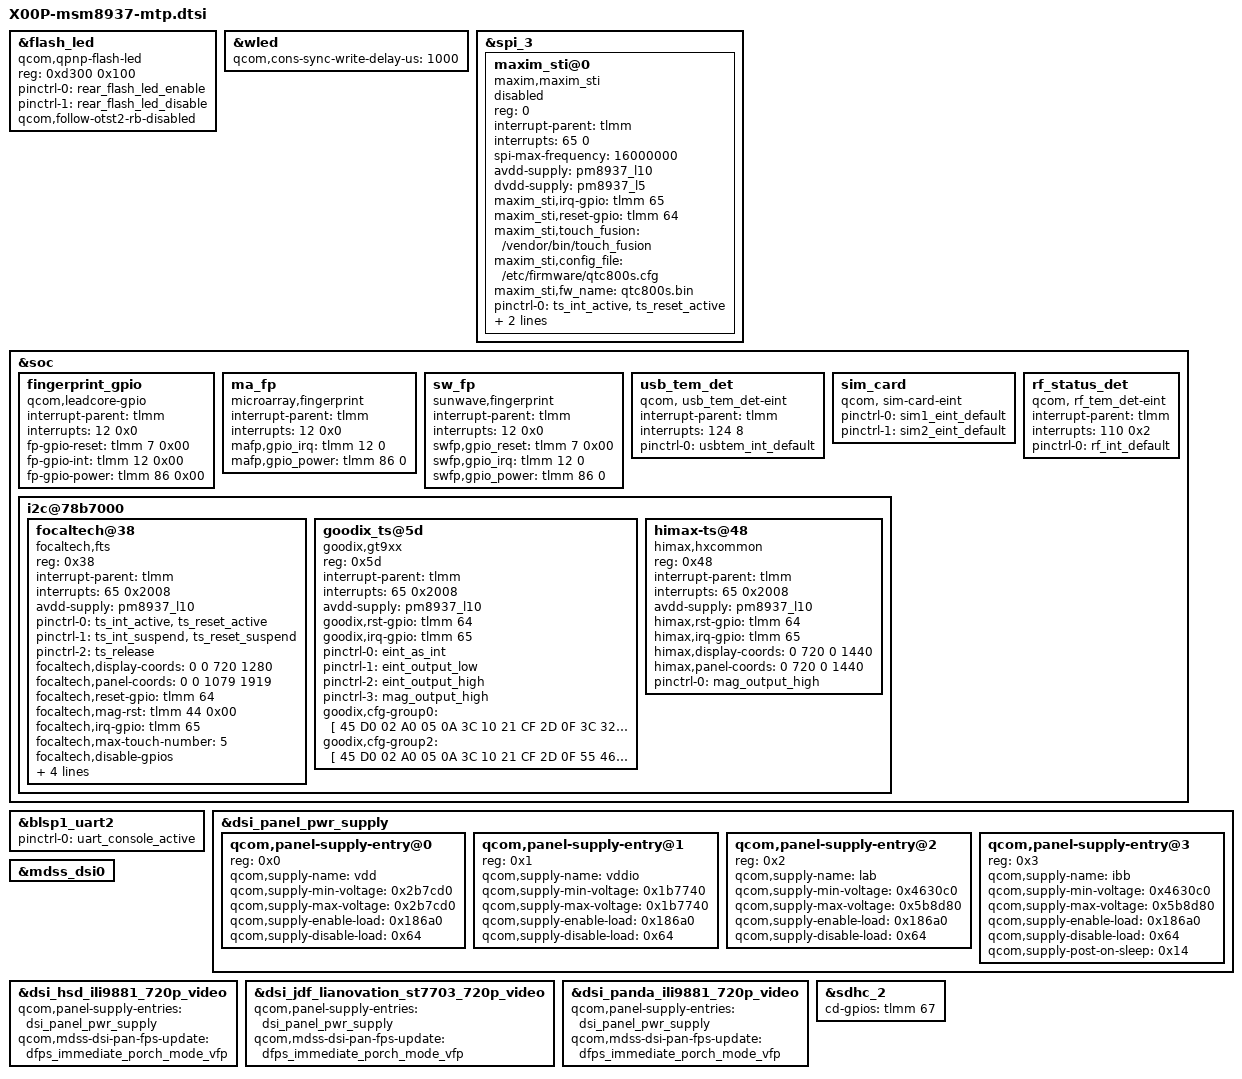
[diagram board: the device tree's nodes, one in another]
/*
 * Copyright (c) 2017, The Linux Foundation. All rights reserved.
 *
 * This program is free software; you can redistribute it and/or modify
 * it under the terms of the GNU General Public License version 2 and
 * only version 2 as published by the Free Software Foundation.
 *
 * This program is distributed in the hope that it will be useful,
 * but WITHOUT ANY WARRANTY; without even the implied warranty of
 * MERCHANTABILITY or FITNESS FOR A PARTICULAR PURPOSE.  See the
 * GNU General Public License for more details.
 */

&flash_led {
	/delete-property/ compatible;
	/delete-property/ reg;
	/delete-property/ pinctrl-names;
	/delete-property/ pinctrl-0;
	/delete-property/ pinctrl-1;
	/delete-property/ qcom,follow-otst2-rb-disabled;
};

&wled {
	/delete-property/ qcom,cons-sync-write-delay-us;
};

&spi_3 {
	maxim_sti@0 {
		status = "disabled";
		compatible = "maxim,maxim_sti";
		reg = <0>;
		interrupt-parent = <&tlmm>;
		interrupts = <65 0>;
		spi-max-frequency = <16000000>;
		avdd-supply = <&pm8937_l10>;
		dvdd-supply = <&pm8937_l5>;
		maxim_sti,irq-gpio = <&tlmm 65 0x00>;
		maxim_sti,reset-gpio = <&tlmm 64 0x00>;
		maxim_sti,touch_fusion = "/vendor/bin/touch_fusion";
		maxim_sti,config_file = "/etc/firmware/qtc800s.cfg";
		maxim_sti,fw_name = "qtc800s.bin";
		pinctrl-names = "pmx_ts_active","pmx_ts_suspend",
			"pmx_ts_release";
		pinctrl-0 = <&ts_int_active &ts_reset_active>;
		pinctrl-1 = <&ts_int_suspend &ts_reset_suspend>;
		pinctrl-2 = <&ts_release>;
	};
};

&soc {
	fingerprint_gpio {
		compatible = "qcom,leadcore-gpio";
		interrupt-parent = <&tlmm>;
		interrupts = <12 0x0>;

		fp-gpio-reset = <&tlmm 7 0x00>;
		fp-gpio-int = <&tlmm  12 0x00>;
		fp-gpio-power = <&tlmm  86 0x00>;
		status = "okay";
	};

	ma_fp {
		compatible = "microarray,fingerprint";
		interrupt-parent = <&tlmm>;
		interrupts = <12 0x0>;
		mafp,gpio_irq = <&tlmm 12 0>;
		mafp,gpio_power = <&tlmm 86 0>;
	};

	sw_fp {
		compatible = "sunwave,fingerprint";
		interrupt-parent = <&tlmm>;
		interrupts = <12 0x0>;
		swfp,gpio_reset = <&tlmm 7 0x00>;
		swfp,gpio_irq = <&tlmm 12 0>;
		swfp,gpio_power = <&tlmm 86 0>;
		status = "okay";
    };	

	usb_tem_det: usb_tem_det {
		compatible = "qcom, usb_tem_det-eint";
    	interrupt-parent = <&tlmm>;
		interrupts = <124 8>;
		pinctrl-names = "default";
		pinctrl-0 = <&usbtem_int_default>;
		status = "okay";
	};	
	
	sim_card: sim_card {
		compatible = "qcom, sim-card-eint";
		pinctrl-names = "sim1_default","sim2_default";
		pinctrl-0 = <&sim1_eint_default>;
		pinctrl-1 = <&sim2_eint_default>;
		status = "ok";
	};

	rf_status_det: rf_status_det {
		compatible = "qcom, rf_tem_det-eint";
		interrupt-parent = <&tlmm>;
		interrupts = <110 0x2>;
		pinctrl-names = "rfstatus";
		pinctrl-0 = <&rf_int_default>;
	};
	
	i2c@78b7000 {
		status = "ok";

		focaltech@38 {
			compatible = "focaltech,fts";
			reg = <0x38>;
			interrupt-parent = <&tlmm>;
			interrupts = <65 0x2008>;
			avdd-supply = <&pm8937_l10>;
			pinctrl-names = "pmx_ts_active","pmx_ts_suspend",
				"pmx_ts_release";
			pinctrl-0 = <&ts_int_active &ts_reset_active>;
			pinctrl-1 = <&ts_int_suspend &ts_reset_suspend>;
			pinctrl-2 = <&ts_release>;
			focaltech,display-coords = <0 0 720 1280>;
			focaltech,panel-coords = <0 0 1079 1919>;
			focaltech,reset-gpio = <&tlmm 64 0x00>;
			focaltech,mag-rst = <&tlmm 44 0x00>;
			focaltech,irq-gpio = <&tlmm 65 0x2008>;
			focaltech,max-touch-number = <5>;
			focaltech,disable-gpios;
			focaltech,button-map = <158 139 172>;
			focaltech,resume-in-workqueue;
			clock-names = "iface_clk", "core_clk";
			clocks = <&clock_gcc clk_gcc_blsp1_ahb_clk>,
				<&clock_gcc clk_gcc_blsp1_qup3_i2c_apps_clk>;
		};

		goodix_ts@5d {
			compatible = "goodix,gt9xx";
			reg = <0x5d>;
			interrupt-parent = <&tlmm>;
			interrupts = <65 0x2008>;
			avdd-supply = <&pm8937_l10>;
			goodix,rst-gpio = <&tlmm 64 0x00>;
			goodix,irq-gpio = <&tlmm 65 0x2008>;
			pinctrl-names = "eint_as_int","eint_output_low", "eint_output_high", "mag_output_high";
			pinctrl-0 = <&eint_as_int>;
			pinctrl-1 = <&eint_output_low>;
			pinctrl-2 = <&eint_output_high>;
			pinctrl-3 = <&mag_output_high>;
			
			goodix,cfg-group0 = [
				45 D0 02 A0 05 0A 3C 10 21 CF 2D
				0F 3C 32 05 F3 00 00 60 62 00 11
				06 15 16 1A 14 87 27 DD 4C 4E D3
				07 7C 06 00 A2 34 11 00 0A 03 02
				19 00 40 0A 0C 62 2A 32 82 88 80
				A5 0A 1E 1E 04 A9 37 00 91 42 00
				7C 50 00 6A 62 00 5D 76 00 5D 00
				00 00 00 F0 50 40 FF F0 17 00 20
				00 03 00 00 00 00 53 64 04 04 0F
				28 00 00 00 00 00 0A 50 19 1E 00
				1E 28 19 18 17 16 15 14 13 12 11
				10 0F 0E 0B 04 05 0C 0D 08 09 0A
				03 02 01 00 07 06 FF FF FF FF 00
				02 04 05 06 08 0A 1E 1F 20 22 24
				29 2A FF FF FF 78 31 00 00 00 87
				70 12 00 00 00 00 14 00 7D 0F 66
				00 44 44 14 88 15 0F 00 00 00 00
				00 00 00 28 5A 00 00 00 00 32 00
				06 00 02 05 78 1C 14 14 28 00 00
				00 00 00 00 00 00 00 00 00 00 00
				00 00 00 00 00 00 20 01];
			goodix,cfg-group2 = [
				45 D0 02 A0 05 0A 3C 10 21 CF 2D
				0F 55 46 05 F3 00 00 60 62 00 11
				06 15 16 1A 14 87 27 DD 4C 4E D3
				07 7C 06 00 C2 33 11 00 00 00 00
				00 C0 40 0A 0C 64 2A 32 82 88 E0
				A5 0A 1E 1E 04 8B 37 00 78 42 00
				67 50 00 5A 62 00 50 76 00 50 00
				00 00 00 F0 50 40 FF F0 17 00 20
				00 00 00 00 00 00 53 64 04 04 0F
				28 00 00 00 00 00 0A 50 00 00 00
				00 28 19 18 17 16 15 14 13 12 11
				10 0F 0E 0B 04 05 0C 0D 08 09 0A
				03 02 01 00 07 06 FF FF FF FF 00
				02 04 05 06 08 0A 1E 1F 20 22 24
				29 2A FF FF FF 78 31 00 00 00 87
				70 12 00 1E 32 32 14 00 7D 0F 66
				00 44 44 14 88 15 0F 00 00 00 00
				00 00 00 28 5A 00 00 00 00 32 00
				06 00 02 05 78 1C 14 14 28 00 00
				00 7E 02 04 00 00 00 00 00 00 00
				00 00 00 00 00 00 A2 01];
		};

		himax-ts@48 {
			compatible = "himax,hxcommon";
			reg = <0x48>;
			interrupt-parent = <&tlmm>;
			interrupts = <65 0x2008>;
			avdd-supply = <&pm8937_l10>;
			himax,rst-gpio = <&tlmm 64 0x00>;
			himax,irq-gpio = <&tlmm 65 0x2008>;
			himax,display-coords = <0 720 0 1440 >;
			himax,panel-coords = <0 720 0 1440>;
			pinctrl-names = "mag_output_high";
			pinctrl-0 = <&mag_output_high>;
		};
	};
};

&flash_led {
	compatible = "qcom,qpnp-flash-led";
	reg = <0xd300 0x100>;
	pinctrl-names = "flash_led_enable","flash_led_disable";
	pinctrl-0 = <&rear_flash_led_enable>;
	pinctrl-1 = <&rear_flash_led_disable>;
	qcom,follow-otst2-rb-disabled;
};

&wled {
	qcom,cons-sync-write-delay-us = <1000>;
};

&blsp1_uart2 {
	status = "ok";
	pinctrl-names = "default";
	pinctrl-0 = <&uart_console_active>;
};

&dsi_panel_pwr_supply {
			#address-cells = <0x1>;
			#size-cells = <0x0>;
			linux,phandle = <0x18e>;
			phandle = <0x18e>;

			qcom,panel-supply-entry@0 {
				reg = <0x0>;
				qcom,supply-name = "vdd";
				qcom,supply-min-voltage = <0x2b7cd0>;
				qcom,supply-max-voltage = <0x2b7cd0>;
				qcom,supply-enable-load = <0x186a0>;
				qcom,supply-disable-load = <0x64>;
			};

			qcom,panel-supply-entry@1 {
				reg = <0x1>;
				qcom,supply-name = "vddio";
				qcom,supply-min-voltage = <0x1b7740>;
				qcom,supply-max-voltage = <0x1b7740>;
				qcom,supply-enable-load = <0x186a0>;
				qcom,supply-disable-load = <0x64>;
			};

			qcom,panel-supply-entry@2 {
				reg = <0x2>;
				qcom,supply-name = "lab";
				qcom,supply-min-voltage = <0x4630c0>;
				qcom,supply-max-voltage = <0x5b8d80>;
				qcom,supply-enable-load = <0x186a0>;
				qcom,supply-disable-load = <0x64>;
			};

			qcom,panel-supply-entry@3 {
				reg = <0x3>;
				qcom,supply-name = "ibb";
				qcom,supply-min-voltage = <0x4630c0>;
				qcom,supply-max-voltage = <0x5b8d80>;
				qcom,supply-enable-load = <0x186a0>;
				qcom,supply-disable-load = <0x64>;
				qcom,supply-post-on-sleep = <0x14>;
			};
		};

&mdss_dsi0 {
	/delete-property/ qcom,dsi-pref-prim-pan;
	/delete-property/ qcom,platform-enable-gpio;
};

&dsi_hsd_ili9881_720p_video {
	qcom,panel-supply-entries = <&dsi_panel_pwr_supply>;
	qcom,mdss-dsi-pan-fps-update = "dfps_immediate_porch_mode_vfp";
};

&dsi_jdf_lianovation_st7703_720p_video {
	qcom,panel-supply-entries = <&dsi_panel_pwr_supply>;
	qcom,mdss-dsi-pan-fps-update = "dfps_immediate_porch_mode_vfp";
};

&dsi_panda_ili9881_720p_video {
	qcom,panel-supply-entries = <&dsi_panel_pwr_supply>;
	qcom,mdss-dsi-pan-fps-update = "dfps_immediate_porch_mode_vfp";
};

&sdhc_2 {
	cd-gpios = <&tlmm 67 0x0>;
};
